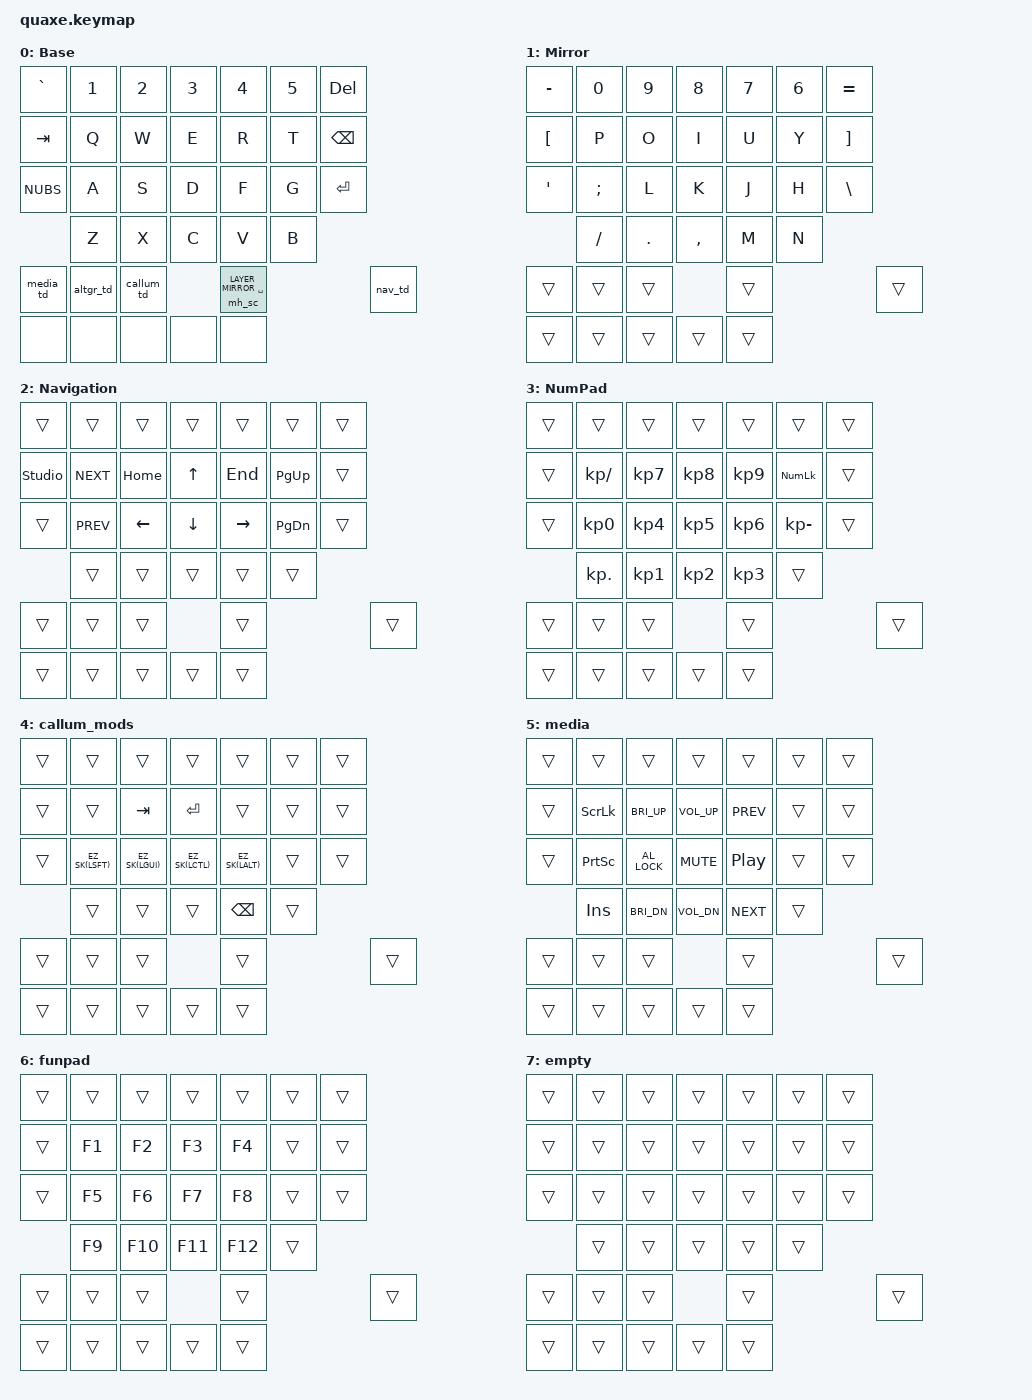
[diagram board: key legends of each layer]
// Standard ZMK headers
#include <behaviors.dtsi>
#include <dt-bindings/zmk/keys.h>
#include <dt-bindings/zmk/pointing.h>

// Community module headers
#include <behaviors/mod-hold.dtsi> // Provides helper macros for the mod-hold behavior

// Timing is key
#define TAPPING_TERM       300
#define SHORT_TAPPING_TERM 150
#define QUICK_TAP          200
#define TAP_DANCE_TERM     250
#define EXTENDED_TAP_TERM  200

// Human-readable layer indexes
#define LAYER_MIRROR  1
#define LAYER_NAV     2
#define LAYER_NUM_PAD 3
#define LAYER_CALLUM  4
#define LAYER_MEDIA   5
#define LAYER_FUNPAD  6

#define PREV LA(LEFT)
#define NEXT LA(RIGHT)

#define EZ_SK(mod) &bsk (mod) (mod)

&sl { ignore-modifiers; }; // keep one-shot-mods when chained into a one-shot-layer
&sk { quick-release; };    // must-have! (lots of false positives otherwise)

// add our common tap-hold parametesr to the default options
&mt {
  tapping-term-ms = <SHORT_TAPPING_TERM>;
  quick-tap-ms = <0>;
};

&lt {
  tapping-term-ms = <TAPPING_TERM>;
  quick-tap-ms = <QUICK_TAP>;
};

/ {
  behaviors {
    // like ZMK's sticky key (sk) but with a more robust timing
    osm: one_shot_modifier {
      compatible = "zmk,behavior-macro-one-param";
      #binding-cells = <1>;
      tap-ms = <0>;
      wait-ms = <0>;
      bindings = <&macro_tap &macro_param_1to1 &sk MACRO_PLACEHOLDER>;
    };

    bsk: better_sticky_key {
      compatible = "zmk,behavior-hold-tap";
      #binding-cells = <2>;
      tapping-term-ms = <TAPPING_TERM>;
      flavor = "tap-preferred";
      bindings = <&kp>, <&osm>;
      hold-while-undecided-linger;
      hold-while-undecided;
    };

    sc: space_cadet { // same as lt, but with hold-preferred
      compatible = "zmk,behavior-hold-tap";
      #binding-cells = <2>;
      tapping-term-ms = <SHORT_TAPPING_TERM>;
      quick-tap-ms = <0>;
      flavor = "hold-preferred";
      bindings = <&mo>, <&kp>;
    };

    lsk: lazy_sticky_key {
      compatible = "zmk,behavior-sticky-key";
      #binding-cells = <1>;
      bindings = <&kp>;
      release-after-ms = <1000>;
      quick-release;
      ignore-modifiers;
      lazy;
    };

    sc_lsk: space_cadet_on_one_shot_mod {
      compatible = "zmk,behavior-hold-tap";
      #binding-cells = <2>;
      tapping-term-ms = <SHORT_TAPPING_TERM>;
      quick-tap-ms = <QUICK_TAP>;
      flavor = "hold-preferred";
      bindings = <&mo>, <&lsk>;
    };

    mo_mod: mods_and_momentary_layer {
      compatible = "zmk,behavior-macro-two-param";
      #binding-cells = <2>;
      tap-ms = <0>;
      wait-ms = <0>;
      bindings = <
        &macro_press
        &macro_param_1to1
        &mo MACRO_PLACEHOLDER
        &macro_param_2to1
        &kp MACRO_PLACEHOLDER

        &macro_pause_for_release
        &macro_release
        &macro_param_1to1
        &mo MACRO_PLACEHOLDER
        &macro_param_2to1
        &kp MACRO_PLACEHOLDER
      >;
    };

    // mod-holds
    MOD_HOLD_1(mh_mo,     &mo,     0xff)
    MOD_HOLD_2(mh_mt,     &mt,     0xff)
    MOD_HOLD_2(mh_sc,     &sc,     0xff)
    MOD_HOLD_2(mh_mo_mod, &mo_mod, 0xff)

    media_td: media_td {
      compatible = "zmk,behavior-tap-dance";
      #binding-cells = <0>;
      tapping-term-ms = <TAP_DANCE_TERM>;
      bindings = <&mh_mo LAYER_MEDIA>, <&mh_mo LAYER_FUNPAD>;
    };

    altgr_td: altgr_td {
      compatible = "zmk,behavior-tap-dance";
      #binding-cells = <0>;
      tapping-term-ms = <TAP_DANCE_TERM>;
      post-tapping-term-ms = <EXTENDED_TAP_TERM>;
      bindings = <&mh_mt RALT ESC>, <&mh_mo_mod LAYER_MIRROR RALT>;
    };

    callum_td: callum_td {
      compatible = "zmk,behavior-tap-dance";
      #binding-cells = <0>;
      tapping-term-ms = <TAP_DANCE_TERM>;
      post-tapping-term-ms = <EXTENDED_TAP_TERM>;
      bindings = <&sc_lsk LAYER_CALLUM LSFT>, <&mh_mo LAYER_MIRROR>;
      eager;
    };

    nav_td: nav_td {
      compatible = "zmk,behavior-tap-dance";
      #binding-cells = <0>;
      tapping-term-ms = <TAP_DANCE_TERM>;
      bindings = <&mh_sc LAYER_NAV ENTER>, <&mh_sc LAYER_NUM_PAD CAPS>;
    };
  };

  keymap {
    compatible = "zmk,keymap";

    base_layer: base_layer {
      display-name = "Base";
      bindings = <
        &kp GRAVE &kp N1 &kp N2 &kp N3 &kp N4 &kp N5 &kp DEL
        &kp TAB   &kp Q  &kp W  &kp E  &kp R  &kp T  &kp BACKSPACE
        &kp NUBS  &kp A  &kp S  &kp D  &kp F  &kp G  &kp ENTER
                  &kp Z  &kp X  &kp C  &kp V  &kp B
        &media_td &altgr_td &callum_td &mh_sc LAYER_MIRROR SPC &nav_td
        &none  &none  &none  &none  &none
      >;
    };

    mirror_layer: mirror_layer {
      display-name = "Mirror";
      bindings = <
        &kp MINUS &kp N0   &kp N9  &kp N8    &kp N7 &kp N6 &kp EQUAL
        &kp LBKT  &kp P    &kp O   &kp I     &kp U  &kp Y  &kp RBKT
        &kp SQT   &kp SEMI &kp L   &kp K     &kp J  &kp H  &kp BSLH
                  &kp FSLH &kp DOT &kp COMMA &kp M  &kp N
                         &trans &trans &trans &trans &trans
        &trans  &trans  &trans  &trans  &trans
      >;
    };

    navigation_layer: navigation_layer {
      display-name = "Navigation";
      bindings = <
        &trans         &trans   &trans   &trans   &trans    &trans    &trans
        &studio_unlock &kp NEXT &kp HOME &kp UP   &kp END   &kp PG_UP &trans
        &trans         &kp PREV &kp LEFT &kp DOWN &kp RIGHT &kp PG_DN &trans
                       &trans   &trans   &trans   &trans    &trans
                       &trans   &trans   &trans   &trans    &trans
        &trans  &trans  &trans  &trans  &trans
      >;
    };

    num_pad_layer: num_pad_layer {
      display-name = "NumPad";
      bindings = <
        &trans &trans       &trans    &trans    &trans    &trans       &trans
        &trans &kp KP_SLASH &kp KP_N7 &kp KP_N8 &kp KP_N9 &kp KP_NUM   &trans
        &trans &kp KP_N0    &kp KP_N4 &kp KP_N5 &kp KP_N6 &kp KP_MINUS &trans
               &kp KP_DOT   &kp KP_N1 &kp KP_N2 &kp KP_N3 &trans
               &trans       &trans    &trans    &trans    &trans
        &trans  &trans  &trans  &trans  &trans
      >;
    };

    callum_mods: callum_mods {
      display-name = "callum_mods";
      bindings = <
        &trans &trans      &trans      &trans      &trans      &trans &trans
        &trans &trans      &kp TAB     &kp ENTER   &trans      &trans &trans
        &trans EZ_SK(LSFT) EZ_SK(LGUI) EZ_SK(LCTL) EZ_SK(LALT) &trans &trans
               &trans      &trans      &trans      &kp BSPC    &trans
                   &trans &trans &trans &trans &trans
        &trans  &trans  &trans  &trans  &trans
      >;
    };

    media_layer: media_layer {
      display-name = "media";
      bindings = <
        &trans  &trans     &trans         &trans        &trans     &trans &trans
        &trans  &kp SLCK   &kp C_BRI_UP   &kp C_VOL_UP  &kp C_PREV &trans &trans
        &trans  &kp PSCRN  &kp C_AL_LOCK  &kp C_MUTE    &kp C_PP   &trans &trans
                &kp INS    &kp C_BRI_DN   &kp C_VOL_DN  &kp C_NEXT &trans
                   &trans &trans &trans &trans &trans
        &trans  &trans  &trans  &trans  &trans
      >;
    };

    funpad_layer: funpad_layer {
      display-name = "funpad";
      bindings = <
        &trans &trans  &trans  &trans  &trans  &trans &trans
        &trans &kp F1  &kp F2  &kp F3  &kp F4  &trans &trans
        &trans &kp F5  &kp F6  &kp F7  &kp F8  &trans &trans
               &kp F9  &kp F10 &kp F11 &kp F12 &trans
                   &trans &trans &trans &trans &trans
        &trans  &trans  &trans  &trans  &trans
      >;
    };

    empty: empty {
      display-name = "empty";
      bindings = <
        &trans &trans &trans &trans &trans &trans &trans
        &trans &trans &trans &trans &trans &trans &trans
        &trans &trans &trans &trans &trans &trans &trans
               &trans &trans &trans &trans &trans
                   &trans &trans &trans &trans &trans
        &trans  &trans  &trans  &trans  &trans
      >;
    };
  };
};
